VERSION ""

NS_ :

BS_:

BU_: VCU BMS

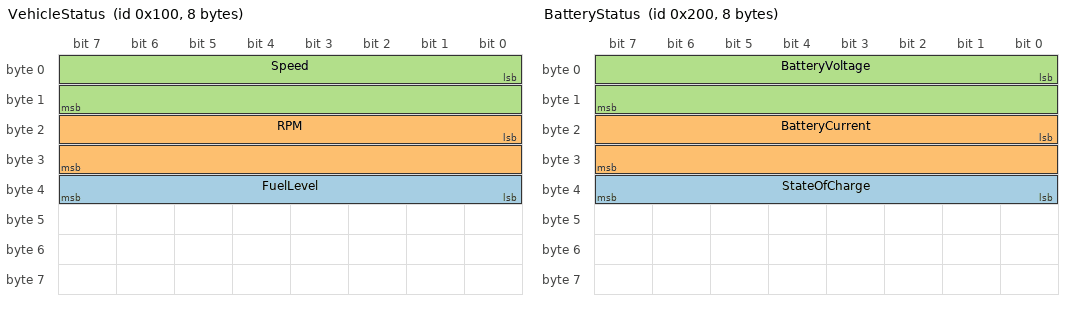
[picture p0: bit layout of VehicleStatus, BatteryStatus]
BO_ 256 VehicleStatus: 8 VCU
 SG_ FuelLevel : 32|8@1+ (1,0) [0|100] "%"  BMS
 SG_ RPM : 16|16@1+ (1,0) [0|8000] "rpm" Vector__XXX
 SG_ Speed : 0|16@1+ (1,0) [0|250] "km/h"  BMS

BO_ 512 BatteryStatus: 8 BMS
 SG_ StateOfCharge : 32|8@1+ (1,0) [0|100] "%"  VCU
 SG_ BatteryCurrent : 16|16@1- (1,0) [0|200] "A"  VCU
 SG_ BatteryVoltage : 0|16@1+ (1,0) [0|500] "V"  VCU

CM_ SG_ 256 FuelLevel "Fuel Level";
CM_ SG_ 256 RPM "Engine RPM";
CM_ SG_ 256 Speed "Vehicle Speed";
CM_ SG_ 512 StateOfCharge "State of Charge";
CM_ SG_ 512 BatteryCurrent "Battery Current";
CM_ SG_ 512 BatteryVoltage "Battery Voltage";
BA_DEF_  "BusType" STRING ;
BA_DEF_ BO_  "GenMsgCycleTime" INT 0 65535;
BA_DEF_ BO_  "VFrameFormat" ENUM  "StandardCAN","ExtendedCAN","reserved","J1939PG","reserved","reserved","reserved","reserved","reserved","reserved","reserved","reserved","reserved","reserved","StandardCAN_FD","ExtendedCAN_FD";
BA_DEF_ BO_  "CANFD_BRS" ENUM  "0","1";
BA_DEF_DEF_  "BusType" "";
BA_DEF_DEF_  "GenMsgCycleTime" 0;
BA_DEF_DEF_  "VFrameFormat" "StandardCAN";
BA_DEF_DEF_  "CANFD_BRS" "1";
BA_ "BusType" "CAN FD";
BA_ "GenMsgCycleTime" BO_ 256 100;
BA_ "GenMsgCycleTime" BO_ 512 200;
